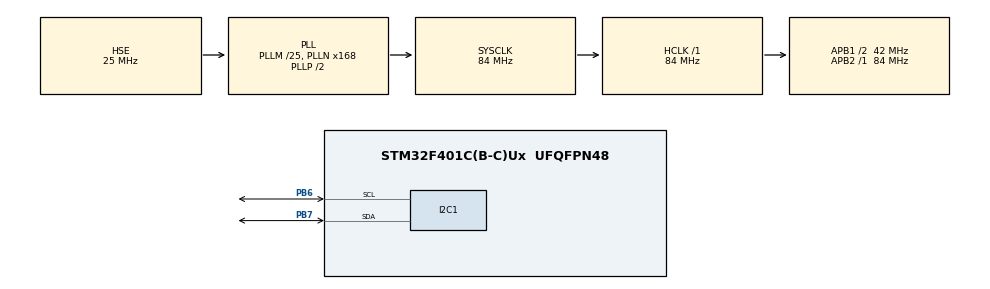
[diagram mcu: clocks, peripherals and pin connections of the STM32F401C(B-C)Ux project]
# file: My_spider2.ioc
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Mcu.Family=STM32F4
Mcu.Name=STM32F401C(B-C)Ux
Mcu.Package=UFQFPN48
NVIC.PriorityGroup=NVIC_PRIORITYGROUP_4
PA13.Mode=Serial_Wire
PA13.Signal=SYS_JTMS-SWDIO
PA14.Mode=Serial_Wire
PA14.Signal=SYS_JTCK-SWCLK
PB6.Mode=I2C
PB6.Signal=I2C1_SCL
PB7.Mode=I2C
PB7.Signal=I2C1_SDA
PH0\ -\ OSC_IN.Mode=HSE-External-Oscillator
PH0\ -\ OSC_IN.Signal=RCC_OSC_IN
PH1\ -\ OSC_OUT.Mode=HSE-External-Oscillator
PH1\ -\ OSC_OUT.Signal=RCC_OSC_OUT
ProjectManager.HeapSize=0x200
ProjectManager.StackSize=0x400
ProjectManager.TargetToolchain=STM32CubeIDE
RCC.48MHZClocksFreq_Value=42000000
RCC.AHBFreq_Value=84000000
RCC.APB1CLKDivider=RCC_HCLK_DIV2
RCC.APB1Freq_Value=42000000
RCC.APB1TimFreq_Value=84000000
RCC.APB2Freq_Value=84000000
RCC.APB2TimFreq_Value=84000000
RCC.CortexFreq_Value=84000000
RCC.HCLKFreq_Value=84000000
RCC.HSE_VALUE=25000000
RCC.HSI_VALUE=16000000
RCC.LSE_VALUE=32768
RCC.PLLM=25
RCC.PLLN=168
RCC.PLLSourceVirtual=RCC_PLLSOURCE_HSE
RCC.SYSCLKFreq_VALUE=84000000
RCC.SYSCLKSource=RCC_SYSCLKSOURCE_PLLCLK
RCC.VCOOutputFreq_Value=168000000
board=custom

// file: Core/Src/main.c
/* USER CODE BEGIN Header */
/**
 ******************************************************************************
 * @file           : main.c
 * @brief          : Main program body
 ******************************************************************************
 * @attention
 *
 * <h2><center>&copy; Copyright (c) 2021 STMicroelectronics.
 * All rights reserved.</center></h2>
 *
 * This software component is licensed by ST under BSD 3-Clause license,
 * the "License"; You may not use this file except in compliance with the
 * License. You may obtain a copy of the License at:
 *                        opensource.org/licenses/BSD-3-Clause
 *
 ******************************************************************************
 */
/** ---------------- SERVO MOTOR ----------------------------------
 * PA6  - timer 3 channel 1
 * clock source = 84 MHz
 * PSC = 40-1
 * ARR = 42000-1
 * pwm freq = 84000000/(42000*40) = 50 Hz
 * Pulse Width (CCR) range: 0-42000
 * Pulse Width (CCR) = 0.5/20*42000=1050     position=0      degree, 0.5ms
 * Pulse Width (CCR) = 1.5/20*60000=3150     position=90     degree, 1.5ms
 * Pulse Width (CCR) = 2.5/20*60000=5250     posistion=180   degree, 2.5ms
 */
/* USER CODE END Header */
#include "main.h"
//#include"My_spider_run.h"
/* USER CODE BEGIN Includes */
#include "pca9685.h"
/* USER CODE END Includes */

/* USER CODE BEGIN PD */
#define SERVO_COUNT 8
//前两条腿
#define SERVO_former_left_up 0
#define SERVO_former_left_dow 8
#define SERVO_former_right_up 2
#define SERVO_former_right_dow 10

//后两条腿
#define SERVO_after_left_up 6
#define SERVO_after_left_dow 14
#define SERVO_after_right_up 4
#define SERVO_after_right_dow 12
/* USER CODE END PD */

I2C_HandleTypeDef hi2c1;

/* USER CODE BEGIN PV */
uint8_t ActiveServo;
/* USER CODE END PV */

void SystemClock_Config(void);
static void MX_GPIO_Init(void);
static void MX_I2C1_Init(void);

int main(void)
{

	/* MCU Configuration--------------------------------------------------------*/

	/* Reset of all peripherals, Initializes the Flash interface and the Systick. */
	HAL_Init();

	/* Configure the system clock */
	SystemClock_Config();

	/* Initialize all configured peripherals */
	MX_GPIO_Init();
	MX_I2C1_Init();
	/* USER CODE BEGIN 2 */
	PCA9685_Init(&hi2c1);
	PCA9685_SetServoAngle(SERVO_former_left_up, 100); // 100度在机器45度
	PCA9685_SetServoAngle(SERVO_former_left_dow, 50); // 50度站起来
	PCA9685_SetServoAngle(SERVO_former_right_up, 100);
	PCA9685_SetServoAngle(SERVO_former_right_dow, 50);
	PCA9685_SetServoAngle(SERVO_after_left_up, 100);
	PCA9685_SetServoAngle(SERVO_after_left_dow, 50);
	PCA9685_SetServoAngle(SERVO_after_right_up, 100);
	PCA9685_SetServoAngle(SERVO_after_right_dow, 50);

	/* USER CODE END 2 */

	/* Infinite loop */
	while (1)
	{
		/*for (uint8_t Angle = 0; Angle < 180; Angle++) {
				PCA9685_SetServoAngle(ActiveServo, Angle);
			  }
			HAL_Delay(500);
			for (uint16_t Angle = 180; Angle > 0; Angle--) {
				PCA9685_SetServoAngle(ActiveServo, Angle);//个数，角度
			}
			HAL_Delay(500);
			ActiveServo++;
			if (ActiveServo >= SERVO_COUNT) ActiveServo = 0;*/
		//测试
		//四足上肢
		// 90度循环
		/* HAL_Delay(1000);

		 for(int i=100;i<150;i++)
				 {
					 PCA9685_SetServoAngle(SERVO_former_left_up, i);
					 //PCA9685_SetServoAngle(SERVO_former_left_dow, i);
					 PCA9685_SetServoAngle(SERVO_former_right_up, i);
					 //PCA9685_SetServoAngle(SERVO_former_right_dow, i);
					 PCA9685_SetServoAngle(SERVO_after_left_up, i);
					 //PCA9685_SetServoAngle(SERVO_after_left_dow, i);//
					 PCA9685_SetServoAngle(SERVO_after_right_up, i);
					 //PCA9685_SetServoAngle(SERVO_after_right_dow, i);
					 HAL_Delay(20);
				 }*/
		//四肢摆动

		HAL_Delay(1000);

		for (int i = 50; i < 110; i++)
		{
			PCA9685_SetServoAngle(SERVO_former_left_dow, i);
			PCA9685_SetServoAngle(SERVO_after_right_dow, i);
			HAL_Delay(5);
		}

		for (int i = 100; i < 170; i++)
		{
			PCA9685_SetServoAngle(SERVO_former_left_up, i);
			// PCA9685_SetServoAngle(SERVO_former_left_dow, i);
			// PCA9685_SetServoAngle(SERVO_former_right_up, i);
			// PCA9685_SetServoAngle(SERVO_former_right_dow, i);
			// PCA9685_SetServoAngle(SERVO_after_left_up, i);
			// PCA9685_SetServoAngle(SERVO_after_left_dow, i);//
			PCA9685_SetServoAngle(SERVO_after_right_up, i);
			// PCA9685_SetServoAngle(SERVO_after_right_dow, i);
			HAL_Delay(5);
		}

		for (int i = 110; i > 50; i--)
		{
			PCA9685_SetServoAngle(SERVO_former_left_dow, i);
			PCA9685_SetServoAngle(SERVO_after_right_dow, i);
			HAL_Delay(5);
		}

		/*for(int i=150;i>100;i--)
						  {
							  PCA9685_SetServoAngle(SERVO_former_left_up, i);
							  //PCA9685_SetServoAngle(SERVO_former_left_dow, i);
							  //PCA9685_SetServoAngle(SERVO_former_right_up, i);
							  //PCA9685_SetServoAngle(SERVO_former_right_dow, i);
							  //PCA9685_SetServoAngle(SERVO_after_left_up, i);
							  //PCA9685_SetServoAngle(SERVO_after_left_dow, i);//
							  PCA9685_SetServoAngle(SERVO_after_right_up, i);
							  //PCA9685_SetServoAngle(SERVO_after_right_dow, i);
							  HAL_Delay(5);
						  }*/

		for (int i = 50; i < 110; i++)
		{
			PCA9685_SetServoAngle(SERVO_former_right_dow, i);
			PCA9685_SetServoAngle(SERVO_after_left_dow, i);
			HAL_Delay(5);
		}

		for (int i = 100; i < 170; i++)
		{
			// PCA9685_SetServoAngle(SERVO_former_left_up, i);
			// PCA9685_SetServoAngle(SERVO_former_left_dow, i);
			PCA9685_SetServoAngle(SERVO_former_right_up, i);
			// PCA9685_SetServoAngle(SERVO_former_right_dow, i);
			PCA9685_SetServoAngle(SERVO_after_left_up, i);
			// PCA9685_SetServoAngle(SERVO_after_left_dow, i);//
			// PCA9685_SetServoAngle(SERVO_after_right_up, i);
			// PCA9685_SetServoAngle(SERVO_after_right_dow, i);
			HAL_Delay(5);
		}

		for (int i = 110; i > 50; i--)
		{
			PCA9685_SetServoAngle(SERVO_former_right_dow, i);
			PCA9685_SetServoAngle(SERVO_after_left_dow, i);
			HAL_Delay(5);
		}

		for (int i = 170; i > 100; i--)
		{
			PCA9685_SetServoAngle(SERVO_former_left_up, i);
			// PCA9685_SetServoAngle(SERVO_former_left_dow, i);
			PCA9685_SetServoAngle(SERVO_former_right_up, i);
			// PCA9685_SetServoAngle(SERVO_former_right_dow, i);
			PCA9685_SetServoAngle(SERVO_after_left_up, i);
			// PCA9685_SetServoAngle(SERVO_after_left_dow, i);//
			PCA9685_SetServoAngle(SERVO_after_right_up, i);
			// PCA9685_SetServoAngle(SERVO_after_right_dow, i);
			HAL_Delay(5);
		}

		//双腿同步

		HAL_Delay(1000);

		/*for(int i=150;i>50;i--)
				{
					//PCA9685_SetServoAngle(SERVO_former_left_up, i);
					PCA9685_SetServoAngle(SERVO_former_left_dow, i);
					//PCA9685_SetServoAngle(SERVO_former_right_up, i);
					PCA9685_SetServoAngle(SERVO_former_right_dow, i);
					//PCA9685_SetServoAngle(SERVO_after_left_up, i);
					 PCA9685_SetServoAngle(SERVO_after_left_dow, i);
					PCA9685_SetServoAngle(SERVO_after_right_up, i);
					PCA9685_SetServoAngle(SERVO_after_right_dow, i);
				  HAL_Delay(20);
				}*/

		/*for(int i=150;i>100;i--)
				 {
					 PCA9685_SetServoAngle(SERVO_former_left_up, i);
					 //PCA9685_SetServoAngle(SERVO_former_left_dow, i);
					 PCA9685_SetServoAngle(SERVO_former_right_up, i);
					 //PCA9685_SetServoAngle(SERVO_former_right_dow, i);
					 PCA9685_SetServoAngle(SERVO_after_left_up, i);
					 //PCA9685_SetServoAngle(SERVO_after_left_dow, i);//
					 PCA9685_SetServoAngle(SERVO_after_right_up, i);
					 //PCA9685_SetServoAngle(SERVO_after_right_dow, i);
					 HAL_Delay(20);
				 }

	 HAL_Delay(1000);

	 for(int i=100;i>50;i--)
					 {
						 PCA9685_SetServoAngle(SERVO_former_left_up, i);
						 //PCA9685_SetServoAngle(SERVO_former_left_dow, i);
						 PCA9685_SetServoAngle(SERVO_former_right_up, i);
						 //PCA9685_SetServoAngle(SERVO_former_right_dow, i);
						 PCA9685_SetServoAngle(SERVO_after_left_up, i);
						 //PCA9685_SetServoAngle(SERVO_after_left_dow, i);//
						 PCA9685_SetServoAngle(SERVO_after_right_up, i);
						 //PCA9685_SetServoAngle(SERVO_after_right_dow, i);
						 HAL_Delay(20);
					 }
	 HAL_Delay(1000);

	 for(int i=50;i<100;i++)
				 {
					 PCA9685_SetServoAngle(SERVO_former_left_up, i);
					 //PCA9685_SetServoAngle(SERVO_former_left_dow, i);
					 PCA9685_SetServoAngle(SERVO_former_right_up, i);
					 //PCA9685_SetServoAngle(SERVO_former_right_dow, i);
					 PCA9685_SetServoAngle(SERVO_after_left_up, i);
					 //PCA9685_SetServoAngle(SERVO_after_left_dow, i);//
					 PCA9685_SetServoAngle(SERVO_after_right_up, i);
					 //PCA9685_SetServoAngle(SERVO_after_right_dow, i);
					 HAL_Delay(20);
				 }

			 HAL_Delay(1000);*/

		//四足下肢

		/*for(int i=0;i<90;i++)
		{
			 PCA9685_SetServoAngle(SERVO_former_left_up, i);
			 PCA9685_SetServoAngle(SERVO_former_right_up, i);
			 PCA9685_SetServoAngle(SERVO_after_left_up, i);
			 PCA9685_SetServoAngle(SERVO_after_right_up, i);
		}

		for(int i=90;i>0;i--)
			{
				 PCA9685_SetServoAngle(SERVO_former_left_up, i);
				 PCA9685_SetServoAngle(SERVO_former_right_up, i);
				 PCA9685_SetServoAngle(SERVO_after_left_up, i);
				 PCA9685_SetServoAngle(SERVO_after_right_up, i);
			}*/

	}
}

void SystemClock_Config(void)
{
	RCC_OscInitTypeDef RCC_OscInitStruct = {0};
	RCC_ClkInitTypeDef RCC_ClkInitStruct = {0};

	/** Configure the main internal regulator output voltage
	 */
	__HAL_RCC_PWR_CLK_ENABLE();
	__HAL_PWR_VOLTAGESCALING_CONFIG(PWR_REGULATOR_VOLTAGE_SCALE2);
	/** Initializes the RCC Oscillators according to the specified parameters
	 * in the RCC_OscInitTypeDef structure.
	 */
	RCC_OscInitStruct.OscillatorType = RCC_OSCILLATORTYPE_HSE;
	RCC_OscInitStruct.HSEState = RCC_HSE_ON;
	RCC_OscInitStruct.PLL.PLLState = RCC_PLL_ON;
	RCC_OscInitStruct.PLL.PLLSource = RCC_PLLSOURCE_HSE;
	RCC_OscInitStruct.PLL.PLLM = 25;
	RCC_OscInitStruct.PLL.PLLN = 168;
	RCC_OscInitStruct.PLL.PLLP = RCC_PLLP_DIV2;
	RCC_OscInitStruct.PLL.PLLQ = 4;
	if (HAL_RCC_OscConfig(&RCC_OscInitStruct) != HAL_OK)
	{
		Error_Handler();
	}
	/** Initializes the CPU, AHB and APB buses clocks
	 */
	RCC_ClkInitStruct.ClockType = RCC_CLOCKTYPE_HCLK | RCC_CLOCKTYPE_SYSCLK | RCC_CLOCKTYPE_PCLK1 | RCC_CLOCKTYPE_PCLK2;
	RCC_ClkInitStruct.SYSCLKSource = RCC_SYSCLKSOURCE_PLLCLK;
	RCC_ClkInitStruct.AHBCLKDivider = RCC_SYSCLK_DIV1;
	RCC_ClkInitStruct.APB1CLKDivider = RCC_HCLK_DIV2;
	RCC_ClkInitStruct.APB2CLKDivider = RCC_HCLK_DIV1;

	if (HAL_RCC_ClockConfig(&RCC_ClkInitStruct, FLASH_LATENCY_2) != HAL_OK)
	{
		Error_Handler();
	}
}

static void MX_I2C1_Init(void)
{

	hi2c1.Instance = I2C1;
	hi2c1.Init.ClockSpeed = 100000;
	hi2c1.Init.DutyCycle = I2C_DUTYCYCLE_2;
	hi2c1.Init.OwnAddress1 = 0;
	hi2c1.Init.AddressingMode = I2C_ADDRESSINGMODE_7BIT;
	hi2c1.Init.DualAddressMode = I2C_DUALADDRESS_DISABLE;
	hi2c1.Init.OwnAddress2 = 0;
	hi2c1.Init.GeneralCallMode = I2C_GENERALCALL_DISABLE;
	hi2c1.Init.NoStretchMode = I2C_NOSTRETCH_DISABLE;
	if (HAL_I2C_Init(&hi2c1) != HAL_OK)
	{
		Error_Handler();
	}
}

static void MX_GPIO_Init(void)
{

	/* GPIO Ports Clock Enable */
	__HAL_RCC_GPIOH_CLK_ENABLE();
	__HAL_RCC_GPIOA_CLK_ENABLE();
	__HAL_RCC_GPIOB_CLK_ENABLE();
}

void Error_Handler(void)
{
	__disable_irq();
	while (1)
	{
	}
}

/************************ (C) COPYRIGHT STMicroelectronics *****END OF FILE****/
